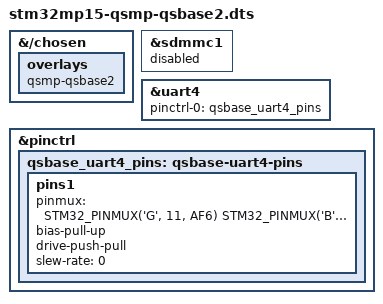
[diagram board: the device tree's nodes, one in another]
// SPDX-License-Identifier: (GPL-2.0-only OR BSD-3-Clause)
/*
 * Copyright (C) 2022 Lothar Waßmann <LW@KARO-electronics.de>
 */

/dts-v1/;

/plugin/;

#include <dt-bindings/pinctrl/stm32-pinfunc.h>

&{/chosen} {
	overlays {
		qsmp-qsbase2;
	};
};

&sdmmc1 {
	status = "disabled";
};

&uart4 {
	pinctrl-0 = <&qsbase_uart4_pins>;
};

&pinctrl {
	qsbase_uart4_pins: qsbase-uart4-pins {
		pins1 {
			pinmux = <
				STM32_PINMUX('G', 11, AF6) /* UART4_TX */
				STM32_PINMUX('B', 2, AF8) /* UART4_RX */
			>;
			bias-pull-up;
			drive-push-pull;
			slew-rate = <0>;
		};
	};
};
